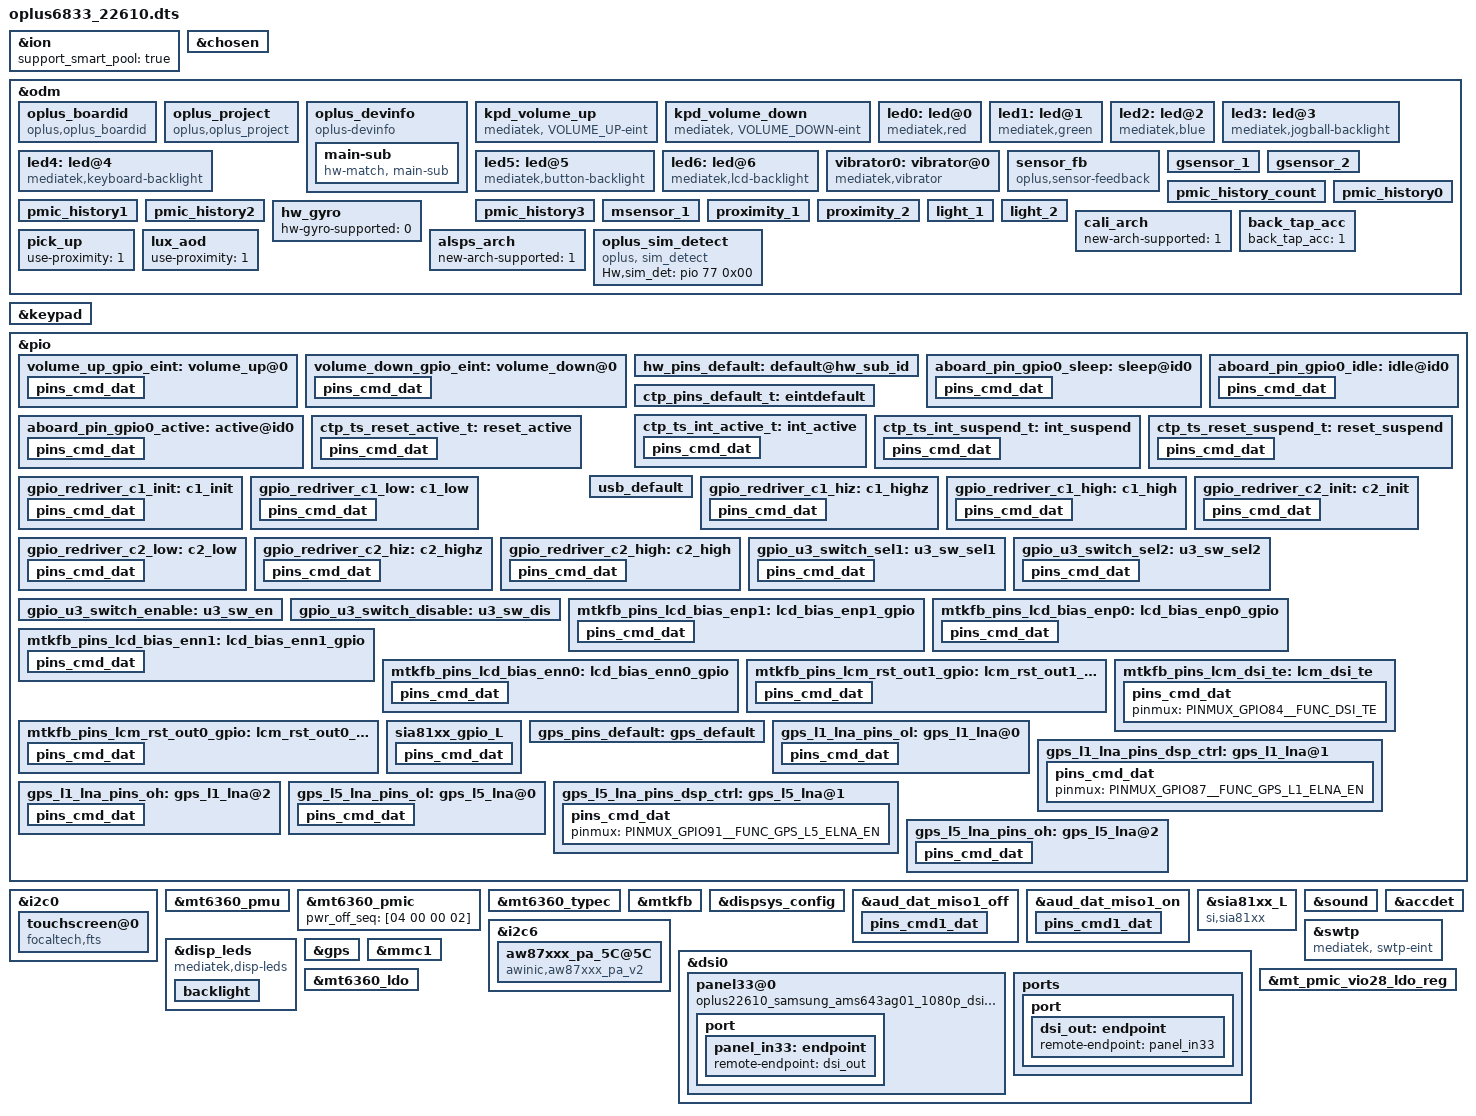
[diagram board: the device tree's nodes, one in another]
// SPDX-License-Identifier: GPL-2.0
/*
 * Copyright (c) 2019 MediaTek Inc.
 *
 */
/dts-v1/;
/plugin/;
#include <dt-bindings/interrupt-controller/irq.h>
#include <dt-bindings/interrupt-controller/arm-gic.h>
#ifndef CONFIG_FPGA_EARLY_PORTING
#include <dt-bindings/pinctrl/mt6833-pinfunc.h>
#endif

/* #ifdef CONFIG_UFF_FINGERPRINT */
#include "mediatek/oplus_uff_22610.dtsi"
/* #endif CONFIG_UFF_FINGERPRINT */

&ion {
	support_smart_pool = "true";
};

/* chosen */
&chosen {
	atag,videolfb-fb_base_l = <0x7e605000>;
	atag,videolfb-fb_base_h = <0x0>;
	atag,videolfb-islcmfound = <1>;
	atag,videolfb-islcm_inited = <0>;
	atag,videolfb-fps= <6000>;
	atag,videolfb-vramSize= <0x1be0000>;
	atag,videolfb-lcmname=
		"nt35595_fhd_dsi_cmd_truly_nt50358_drv";
};

&odm {
	oplus_boardid:oplus_boardid {
		compatible = "oplus,oplus_boardid";
		oplus_boardid,dtsino="22610";//only one u32
		oplus_boardid,pcbmask="0xffff";//all mask 0xffff
	};
	oplus_project:oplus_project {
		compatible = "oplus,oplus_project";
	};

	oplus_devinfo:oplus_devinfo {
		compatible = "oplus-devinfo";
		pinctrl-names = "default", "aboard_gpio0_sleep", "aboard_gpio0_active", "aboard_gpio0_idle";
		pinctrl-0 = <&hw_pins_default>;
		pinctrl-1 = <&aboard_pin_gpio0_sleep>;
		pinctrl-2 = <&aboard_pin_gpio0_active>;
		pinctrl-3 = <&aboard_pin_gpio0_idle>;
		main-sub {
			use_tristate_gpio;
			compatible = "hw-match, main-sub";
			aboard-gpio0 = <&pio 91 0x00>;
			aboard-patterns = <0>;	/*0[high-resistance] 1[pull-down] 2[pull-up]*/
			/*main board*/
			match-projects = <22610>;
		};
	};

	kpd_volume_up:kpd_volume_up {
		compatible = "mediatek, VOLUME_UP-eint";
		interrupt-parent = <&pio>;
		interrupts = <1 IRQ_TYPE_EDGE_FALLING 1 0>;
		debounce = <32000>;
		status = "okay";
	};

	kpd_volume_down:kpd_volume_down {
		compatible = "mediatek, VOLUME_DOWN-eint";
		interrupt-parent = <&pio>;
		interrupts = <80 IRQ_TYPE_EDGE_FALLING 80 0>;
		debounce = <32000>;
		status = "okay";
	};
};
&keypad {
	keypad,volume-up	= <&pio 1 0x00>;
	keypad,volume-down	= <&pio 80 0x00>;
	pinctrl-names = "volume_up_as_int", "volume_down_as_int";
	pinctrl-0 = <&volume_up_gpio_eint>;
	pinctrl-1 = <&volume_down_gpio_eint>;
	status = "okay";
};
&pio {
	volume_up_gpio_eint:volume_up@0{
		pins_cmd_dat {
			pinmux = <PINMUX_GPIO1__FUNC_GPIO1>;
			slew-rate = <0>;  /*direction 0:in, 1:out*/
			input-enable;
		};
	};

	volume_down_gpio_eint:volume_down@0{
		pins_cmd_dat {
			pinmux = <PINMUX_GPIO80__FUNC_GPIO80>;
			slew-rate = <0>;  /*direction 0:in, 1:out*/
			input-enable;
		};
	};

	hw_pins_default:default@hw_sub_id {
	};
	aboard_pin_gpio0_sleep:sleep@id0 {
		pins_cmd_dat {
			pinmux = <PINMUX_GPIO91__FUNC_GPIO91>;
			slew-rate = <0>;
			bias-pull-down;
			input-enable;
		};
	};

	aboard_pin_gpio0_active:active@id0 {
		pins_cmd_dat {
			pinmux = <PINMUX_GPIO91__FUNC_GPIO91>;
			slew-rate = <0>;
			bias-pull-up;
			input-enable;
		};
	};

	aboard_pin_gpio0_idle:idle@id0 {
		pins_cmd_dat {
			pinmux = <PINMUX_GPIO91__FUNC_GPIO91>;
			slew-rate = <0>;
			bias-disable;
			input-enable;
		};
	};
};

/* 2022.12.31,Hawaii add for tp ic 3518 dts bringup */
&i2c0 {
	status = "okay";
	#address-cells = <1>;
	#size-cells = <0>;

	touchscreen@0 {
		compatible = "focaltech,fts";
		reg = <0x38>;
		chip-name = "FT3518";
		status = "okay";

		//spi-max-frequency = <9600000>;	//4800000,9600000,15000000,19200000
		interrupt-parent = <&pio>;
		interrupts = <14 0x2002>;
		irq-gpio = <&pio 14 0x2002>;
		reset-gpio = <&pio 15 0x1>;

		/* Power Config */
		//vdd_2v8-supply  = <&mt_pmic_vtp_ldo_reg>;
		//vdd_2v8_volt = <3000000>;

		/*driver match info*/
		vid_len = <2>;
		tp_type = <8>; /*type:21 txd*/
		platform_support_project = <22610 22705 22706 22740 22741>;
		platform_support_project_dir = <22610 22705 22706 22740 22741>;
		platform_support_project_commandline = "default_commandline", "default_commandline", "default_commandline", "default_commandline", "default_commandline";

		/*panel properities*/
		touchpanel,max-num-support = <10>;
		touchpanel,tx-rx-num = <16 34>;
		touchpanel,panel-coords = <4320 9600>;
		touchpanel,display-coords = <1080 2400>;
		touchpanel,touchmajor-limit = <0 216>;
		touchpanel,report-rate = <120 240>;
		touchpanel,smooth-level = <255 2 15 25 45 60>;
		touchpanel,smooth-level-charging = <255 15 20 25 45 60>;
		touchpanel,sensitive-level = <255 20 16 13 10 5>;
		touchpanel,single-optimized-time = <8>;
		touchpanel,high-frame-rate-time = <20>;

		/*sw-feature*/
		//incell_screen;
		//irq_need_dev_resume_ok;
		fw_edge_limit_support;
		black_gesture_support;
		charger_pump_support;
		headset_pump_support;
		//esd_handle_support;
		//black_gesture_test_support;
		game_switch_support;
		//noflash_support;
		//lcd_trigger_load_tp_fw_support;
		smart_gesture_support;
		pressure_report_support;
		fw_update_app_support;
		health_monitor_v2_support;
		fw_update_in_probe_with_headfile;
		fingerprint_underscreen_support;
		high_resolution_support;
		//disable_suspend_irq_handler_support;
		sportify_aod_gesture_support;
		black_gesture_indep_support;
		exception_upload_support;
		//snr_read_support;

		touchpanel,button-type = <4>;
		touchpanel.button-TRx = <0 0>;
	};

};

&pio {
	ctp_pins_default_t: eintdefault {
	};
	ctp_ts_int_active_t: int_active {
		pins_cmd_dat {
			pinmux = <PINMUX_GPIO14__FUNC_GPIO14>;
			slew-rate = <0>;
			bias-pull-down = <0>;
		};
	};
	ctp_ts_reset_active_t: reset_active {
		pins_cmd_dat {
			pinmux = <PINMUX_GPIO15__FUNC_GPIO15>;
			slew-rate = <1>;
			output-high;
		};
	};
	ctp_ts_int_suspend_t: int_suspend {
		pins_cmd_dat {
			pinmux = <PINMUX_GPIO14__FUNC_GPIO14>;
			slew-rate = <1>;
			output-low;
		};
	};
	ctp_ts_reset_suspend_t: reset_suspend {
		pins_cmd_dat {
			pinmux = <PINMUX_GPIO15__FUNC_GPIO15>;
			slew-rate = <0>;
			output-low;
		};
	};
};
/*TOUCH END*/

/* USB SWITCH GPIO start */
&pio {
	usb_default: usb_default {
	};

	gpio_redriver_c1_init: c1_init {
		pins_cmd_dat {
			pinmux = <PINMUX_GPIO41__FUNC_GPIO41>;
			slew-rate = <1>;
			output-low;
		};
	};

	gpio_redriver_c1_low: c1_low {
		pins_cmd_dat {
			pinmux = <PINMUX_GPIO41__FUNC_GPIO41>;
			slew-rate = <1>;
			output-low;
		};
	};

	gpio_redriver_c1_hiz: c1_highz {
		pins_cmd_dat {
			pinmux = <PINMUX_GPIO41__FUNC_GPIO41>;
			slew-rate= <0>;
			bias-disable;
		};
	};

	gpio_redriver_c1_high: c1_high {
		pins_cmd_dat {
			pinmux = <PINMUX_GPIO41__FUNC_GPIO41>;
			slew-rate = <1>;
			output-high;
		};
	};

	gpio_redriver_c2_init: c2_init {
		pins_cmd_dat {
			pinmux = <PINMUX_GPIO40__FUNC_GPIO40>;
			slew-rate = <1>;
			output-low;
		};
	};

	gpio_redriver_c2_low: c2_low {
		pins_cmd_dat {
			pinmux = <PINMUX_GPIO40__FUNC_GPIO40>;
			slew-rate = <1>;
			output-low;
		};
	};

	gpio_redriver_c2_hiz: c2_highz {
		pins_cmd_dat {
			pinmux = <PINMUX_GPIO40__FUNC_GPIO40>;
			slew-rate= <0>;
			bias-disable;
		};
	};

	gpio_redriver_c2_high: c2_high {
		pins_cmd_dat {
			pinmux = <PINMUX_GPIO40__FUNC_GPIO40>;
			slew-rate = <1>;
			output-high;
		};
	};

	gpio_u3_switch_sel1: u3_sw_sel1 {
		pins_cmd_dat {
			pinmux = <PINMUX_GPIO11__FUNC_GPIO11>;
			slew-rate = <1>;
			output-low;
		};
	};

	gpio_u3_switch_sel2: u3_sw_sel2 {
		pins_cmd_dat {
			pinmux = <PINMUX_GPIO11__FUNC_GPIO11>;
			slew-rate = <1>;
			output-high;
		};
	};

	gpio_u3_switch_enable: u3_sw_en {
	};

	gpio_u3_switch_disable: u3_sw_dis {
	};
};

&mt6360_pmu {
	mt6360,intr_gpio_num = <10>; /* direct defined GPIO num */
	mt6360,intr_gpio = <&pio 10 0x0>;
};

&mt6360_pmic {
	pwr_off_seq = [04 00 00 02];
};

&mt6360_typec {
	mt6360pd,intr_gpio_num = <9>; /* direct defined GPIO num */
	mt6360pd,intr_gpio = <&pio 9 0x0>;
};

#ifndef CONFIG_FPGA_EARLY_PORTING
&pio {
	mtkfb_pins_lcd_bias_enp1: lcd_bias_enp1_gpio {
		pins_cmd_dat {
			pinmux = <PINMUX_GPIO137__FUNC_GPIO137>;
			slew-rate = <1>;
			output-high;
		};
	};

	mtkfb_pins_lcd_bias_enp0: lcd_bias_enp0_gpio {
		pins_cmd_dat {
			pinmux = <PINMUX_GPIO137__FUNC_GPIO137>;
			slew-rate = <1>;
			output-low;
		};
	};

	mtkfb_pins_lcd_bias_enn1: lcd_bias_enn1_gpio {
		pins_cmd_dat {
			pinmux = <PINMUX_GPIO138__FUNC_GPIO138>;
			slew-rate = <1>;
			output-high;
		};
	};

	mtkfb_pins_lcd_bias_enn0: lcd_bias_enn0_gpio {
		pins_cmd_dat {
			pinmux = <PINMUX_GPIO138__FUNC_GPIO138>;
			slew-rate = <1>;
			output-low;
		};
	};

	mtkfb_pins_lcm_rst_out1_gpio: lcm_rst_out1_gpio {
		pins_cmd_dat {
			pinmux = <PINMUX_GPIO86__FUNC_GPIO86>;
			slew-rate = <1>;
			output-high;
		};
	};

	mtkfb_pins_lcm_rst_out0_gpio: lcm_rst_out0_gpio {
		pins_cmd_dat {
			pinmux = <PINMUX_GPIO86__FUNC_GPIO86>;
			slew-rate = <1>;
			output-low;
		};
	};
	mtkfb_pins_lcm_dsi_te: lcm_dsi_te {
		pins_cmd_dat {
			pinmux = <PINMUX_GPIO84__FUNC_DSI_TE>;
		};
	};
};

&mtkfb {
	pinctrl-names = "lcd_bias_enp1_gpio", "lcd_bias_enp0_gpio",
		"lcd_bias_enn1_gpio", "lcd_bias_enn0_gpio",
		"lcm_rst_out1_gpio", "lcm_rst_out0_gpio",
		"mode_te_te";
	pinctrl-0 = <&mtkfb_pins_lcd_bias_enp1>;
	pinctrl-1 = <&mtkfb_pins_lcd_bias_enp0>;
	pinctrl-2 = <&mtkfb_pins_lcd_bias_enn1>;
	pinctrl-3 = <&mtkfb_pins_lcd_bias_enn0>;
	pinctrl-4 = <&mtkfb_pins_lcm_rst_out1_gpio>;
	pinctrl-5 = <&mtkfb_pins_lcm_rst_out0_gpio>;
	pinctrl-6 = <&mtkfb_pins_lcm_dsi_te>;
	status = "okay";
};
&dispsys_config {
	pinctrl-names =
		"lcm_rst_out1_gpio", "lcm_rst_out0_gpio",
		"mode_te_te";
	pinctrl-0 = <&mtkfb_pins_lcm_rst_out1_gpio>;
	pinctrl-1 = <&mtkfb_pins_lcm_rst_out0_gpio>;
	pinctrl-2 = <&mtkfb_pins_lcm_dsi_te>;
	status = "okay";

	helper-value = <0>, /*MTK_DRM_OPT_STAGE*/
		<1>, /*MTK_DRM_OPT_USE_CMDQ*/
		<1>, /*MTK_DRM_OPT_USE_M4U*/
		<0>, /*MTK_DRM_OPT_SODI_SUPPORT*/
		<1>, /*MTK_DRM_OPT_IDLE_MGR*/
		<0>, /*MTK_DRM_OPT_IDLEMGR_SWTCH_DECOUPLE*/
		<0>, /*MTK_DRM_OPT_IDLEMGR_BY_REPAINT*/
		<0>, /*MTK_DRM_OPT_IDLEMGR_ENTER_ULPS*/
		<0>, /*MTK_DRM_OPT_IDLEMGR_KEEP_LP11*/
		<0>, /*MTK_DRM_OPT_DYNAMIC_RDMA_GOLDEN_SETTING*/
		<1>, /*MTK_DRM_OPT_IDLEMGR_DISABLE_ROUTINE_IRQ*/
		<0>, /*MTK_DRM_OPT_MET_LOG*/
		<1>, /*MTK_DRM_OPT_USE_PQ*/
		<1>, /*MTK_DRM_OPT_ESD_CHECK_RECOVERY*/
		<1>, /*MTK_DRM_OPT_ESD_CHECK_SWITCH*/
		<1>, /*MTK_DRM_OPT_PRESENT_FENCE*/
		<0>, /*MTK_DRM_OPT_RDMA_UNDERFLOW_AEE*/
		<1>, /*MTK_DRM_OPT_DSI_UNDERRUN_AEE*/
		<1>, /*MTK_DRM_OPT_HRT*/
		<1>, /*MTK_DRM_OPT_HRT_MODE*/
		<0>, /*MTK_DRM_OPT_DELAYED_TRIGGER*/
		<1>, /*MTK_DRM_OPT_OVL_EXT_LAYER*/
		<0>, /*MTK_DRM_OPT_AOD*/
		<1>, /*MTK_DRM_OPT_RPO*/
		<0>, /*MTK_DRM_OPT_DUAL_PIPE*/
		<0>, /*MTK_DRM_OPT_DC_BY_HRT*/
		<0>, /*MTK_DRM_OPT_OVL_WCG*/
		<0>, /*MTK_DRM_OPT_OVL_SBCH*/
		<1>, /*MTK_DRM_OPT_COMMIT_NO_WAIT_VBLANK*/
		<0>, /*MTK_DRM_OPT_MET*/
		<0>, /*MTK_DRM_OPT_REG_PARSER_RAW_DUMP*/
		<0>, /*MTK_DRM_OPT_VP_PQ*/
		<0>, /*MTK_DRM_OPT_GAME_PQ*/
		<0>, /*MTK_DRM_OPT_MMPATH*/
		<1>, /*MTK_DRM_OPT_HBM*/
		<1>, /*MTK_DRM_OPT_VDS_PATH_SWITCH*/
		<0>, /*MTK_DRM_OPT_LAYER_REC*/
		<1>; /*MTK_DRM_OPT_CLEAR_LAYER*/
};

/* add for dual-mic or singlemic with miso1 */
&aud_dat_miso1_off {
	pins_cmd1_dat {
		pinmux = <PINMUX_GPIO160__FUNC_GPIO160>;
		input-enable;
		bias-pull-down;
	};
};
&aud_dat_miso1_on {
	pins_cmd1_dat {
		pinmux = <PINMUX_GPIO160__FUNC_AUD_DAT_MISO1>;
		input-schmitt-enable;
		bias-disable;
	};
};

&pio {
	sia81xx_gpio_L: sia81xx_gpio_L {
		pins_cmd_dat {
			pinmux = <PINMUX_GPIO94__FUNC_GPIO94>;
			slew-rate = <1>;
			bias-disable;
		};
	};
};

&sia81xx_L {
	compatible = "si,sia81xx";
	si,sia81xx_type = "sia8102";
	si,sia81xx_reset = <&pio 94 0>;
	si,sia81xx_owi = <&pio 94 0>;
	si,sia_boost_vol_support = <1>;
	pinctrl-names = "sia81xx_gpio";
	pinctrl-0 = <&sia81xx_gpio_L>;
	si,sia81xx_disable_pin = <0>;
	/* the same value share a same task
	 * valid value range : 0 ~ 7 */
	timer_task_hdl = <0>;
	channel_num = <0>;
	owi_mode = <1>;
	en_x_filter = <0>;
	en_dynamic_updata_vdd = <1>;
	dynamic_updata_vdd_port = <0x8>;
	algo_is_v2 = <1>;
};

&sound {
	/* this dtsi config for product's special config, AudioHal read ctl 'OPLUS_AUDIO_EXTEN_CONFIG' get the values*
	 * 1st value --> PA type: 0:NXP Pa, 1:Awinic Pa 2:sia81xx Pa*/
	audio_extern_config = <2>;
	si,sia81xx-max-num = <1>;
	si,sia81xx-aux-devs = <&sia81xx_L>;
	si,sia81xx-aux-devs-prefix = "SpkrLeft";
};

&i2c6 {
	aw87xxx_pa_5C@5C {
		compatible = "awinic,aw87xxx_pa_v2";
		reset-gpio = <&pio 94 0>;
		reg = <0x5C>;
		dev_index = < 0 >;
		status = "okay";
	};
};

&dsi0 {
	status = "okay";
	#address-cells = <1>;
	#size-cells = <0>;
	panel33@0 {
		compatible = "oplus22610_samsung_ams643ag01_1080p_dsi_cmd";
		reg = <0>;
		reset-gpios = <&pio 86 0>;
		bias-gpios = <&pio 137 0>, <&pio 138 0>;
		pinctrl-names = "default";
		port {
			panel_in33: endpoint {
				remote-endpoint = <&dsi_out>;
			};
		};
	};
	ports {
		port {
			dsi_out: endpoint {
				remote-endpoint = <&panel_in33>;
			};
		};
	};
};
#endif

/* delete default keys pinctrl
&keypad {
	pinctrl-names = "default";
	pinctrl-0 = <&kpd_pins_default>;
};

&pio {
	kpd_pins_default: kpdgpiodefault {
		pins_cmd_dat {
			pinmux = <PINMUX_GPIO79__FUNC_KPCOL0>;
			bias-pull-up = <MTK_PUPD_SET_R1R0_10>;
			output-low;
			input-schmitt-enable;
		};
	};
};
*/

//#include "mediatek/cust_mt6833_touch_1080x2300.dtsi"
/* accdet start */
&accdet {
	/* accdet micbias voltage: 0x09:2.85v 0x08:2.8v 0x07,
	 * 2.7v;0x05,2.5v;0x02,1.9v
	 */
	accdet-mic-vol = <7>;
	/* accdet pwm_width, pwm_thresh, fall_delay, rise_delay
	 * debounce0, debounce1, debounce3, debounce4
	 * eint pwm_width, eint pwm_thresh
	 * eint deb(debounce0, debounce1, debounce2, debounce3), inv_debounce
	 */

	headset-mode-setting = <0x500 0x500 1 0x1f0
				0x1325 0x800 0x3D4 0x44
				0x0 0x7
				0x5 0x9 0x9 0xd 0xe>;
	/*headset-mode-setting = <0x500 0x500 1 0x1f0
	*                      0x800 0x800 0x20 0x44
	*                      0x4 0x1
	*                      0x5 0x3 0x3 0x5 0xe>;
	*/

	accdet-plugout-debounce = <1>;
	/*1:ACC mode, 2:low cost without in bias, 6:low cost with in bias*/
	accdet-mic-mode = <2>;
	/*0--MD_MAX--UP_MAX--DW_MAX*/
	headset-three-key-threshold = <0 82 170 306>;
	//headset-three-key-threshold = <0 80 220 400>;
	headset-three-key-threshold-CDD = <0 121 192 600>;
	/*0--MD_MAX--VOICE_MAX--UP_MAX--DW_MAX*/
	headset-four-key-threshold = <0 58 121 192 400>;
	/* moisture HW mode config start. Enable moisture detection or not
	 * default use HW mode for moisture detection
	 */
	moisture_detect_enable = <1>;
	/* select VTH to 2v and 500k, use internal resitance */
	eint_use_ext_res = <0>;
	/* enable eint detection mode, if moisture detection enable
	 * eint_detect_mode = moisture_detect_mode;otherwise, select
	 * eint_detect_mode = 4 as DEFAULT
	 */
	eint_detect_mode = <5>;
	/* enable moisture detection mode, if moisture detection enable
	 * eint_detect_mode = moisture_detect_mode
	 */
	moisture_detect_mode = <5>;
	/* select 0: 2.8V; 1: 2.4V; 2: 2V; 3: VTH=MVTH(VTH2) */
	moisture_comp_vth = <2>;
//#ifdef OPLUS_BUG_COMPATIBILITY
	moisture_comp_vref2 = <2>;
//#else
	/* vref2 voltage for different water impedance */
	//moisture_comp_vref2 = <0>;
//#endif
	/* moisture HW mode config end */

	/* moisture SW mode config start, use external resister or not.
	 * DEFAULT NOT NEED
	 */
	moisture_use_ext_res = <0>;
	/* moisture external resister ohm, SW mode by auxadc */
	moisture-external-r = <2000000>;
	/* moisture internal resister ohm, SW mode by auxadc */
	moisture-internal-r = <47000>;
	/* moisture of water resister ohm, SW mode by auxadc*/
	moisture-water-r = <10000>;
	/* moisture SW mode config end */
        //#endif /* VENDOR_EDIT */
	status = "okay";
};
/* accdet end */

//#ifdef OPLUS_FEATURE_SWTP
&swtp {
    compatible = "mediatek, swtp-eint";
};
//#endif  /*OPLUS_FEATURE_SWTP*/

&disp_leds {
	compatible = "mediatek,disp-leds";
	backlight {
		label = "lcd-backlight";
		max-brightness = <22527>;
		led-bits = <14>;
		trans-bits = <14>;
		support_silky_brightness = <1>;
		default-state = "on";
	};
};
&mt_pmic_vio28_ldo_reg {
	regulator-name = "vio28";
	regulator-min-microvolt = <3300000>;
	regulator-max-microvolt = <3300000>;
	regulator-enable-ramp-delay = <1920>;
};

&odm {
	led0:led@0 {
		compatible = "mediatek,red";
		led_mode = <0>;
		data = <1>;
		pwm_config = <0 0 0 0 0>;
	};
	led1:led@1 {
		compatible = "mediatek,green";
		led_mode = <0>;
		data = <1>;
		pwm_config = <0 0 0 0 0>;
	};
	led2:led@2 {
		compatible = "mediatek,blue";
		led_mode = <0>;
		data = <1>;
		pwm_config = <0 0 0 0 0>;
	};
	led3:led@3 {
		compatible = "mediatek,jogball-backlight";
		led_mode = <0>;
		data = <1>;
		pwm_config = <0 0 0 0 0>;
	};
	led4:led@4 {
		compatible = "mediatek,keyboard-backlight";
		led_mode = <0>;
		data = <1>;
		pwm_config = <0 0 0 0 0>;
	};
	led5:led@5 {
		compatible = "mediatek,button-backlight";
		led_mode = <0>;
		data = <1>;
		pwm_config = <0 0 0 0 0>;
	};
	led6:led@6 {
		compatible = "mediatek,lcd-backlight";
		led_mode = <4>;
		data = <1>;
		pwm_config = <0 1 0 0 0>;
	};
	vibrator0:vibrator@0 {
		compatible = "mediatek,vibrator";
	};
	sensor_fb: sensor_fb {
		compatible = "oplus,sensor-feedback";
	};

	/*
	enum {
		LIS3DH,
		LSM6DS3,
		BMI160,
		LIS2HH12,
		LSM6DSM,
		BMI2XY,
		LSM6DSO,
		ICM4X6XX,
		SC7A20,
		BMA4XY,
		BMI3XY,
		ICM4N607,
		BMA2X2,
		MC34X9,
		STK8XXX,
	};
	*/

	gsensor_1: gsensor_1 {
		status = "okay";
		sensor_name = <8>;//SC7A20
		device_name = "sc7a20";
		i2c_num = <2>;
		i2c_addr = <0>;
		direction = <4>;
		eint_num = <3>;
		gyro_cali_version= <2>;
		acc_cali_range= <300 300 300>; //300mg
		device_id = <0>; //0 sc7a20,1 sc7a20e
		filter_param_h  = <8>;
	};
	gsensor_2: gsensor_2 {
		status = "okay";
		sensor_name = <9>;//BMA4XY
		device_name = "bma4xy";
		i2c_num = <2>;
		i2c_addr = <0>;
		direction = <10>;
		eint_num = <3>;
		gyro_cali_version= <2>;
		acc_cali_range= <300 300 300>; //300mg
	};
	/*
	enum {
		AKM09911,
		MMC3530,
		MMC5603,
		MXG4300,
		QMC6308,
	};
	*/

	pmic_history_count:pmic_history_count {
	};
	pmic_history0:pmic_history0 {
	};
	pmic_history1:pmic_history1 {
	};
	pmic_history2:pmic_history2 {
	};
	pmic_history3:pmic_history3 {
	};

	msensor_1: msensor_1 {
		status = "okay";
		sensor_name = <2>;//MMC5603
		i2c_num = <0>;
		i2c_addr = <48>;
		direction = <1>;
		eint_num = <0>;
		soft-mag-parameter = <9990 0 115 1 352 0 65 0 9840 0 70 0 80 0 407 1 10204 0>;
	};

	/*
	enum {
		TMD2725,
		APSD9922,
		STK3335,
		STK3331,
		STK2232,
		TCS3701,
		STK32600,
		STK33502,
		MN78911,
		TMD2755x12,
	};
	*/
	proximity_1: proximity_1 {
		status = "okay";
		sensor_name = <6>;//STK32600
		i2c_num = <0>;
		i2c_addr = <0x48>;
		direction = <4>;
		eint_num = <2>;
		low_step = <300>;
		high_step = <400>;
		low_limit = <650>;
		high_limit = <1050>;
		dirty_low_step = <300>;
		dirty_high_step = <400>;
		ps_dirty_limit = <1800>;
		ps_ir_limit = <2000>;
		ps_adjust_min = <0>;
		ps_adjust_max = <1850>;
		sampling_count = <5>;
		step_max = <400>;
		step_min = <100>;
		step_div = <2000>;
		anti_shake_delta = <70>;
		dynamic_cali_max = <2000>;
		raw2offset_radio = <1000>;
		offset_max = <60000>;
		offset_range_min = <0>;
		offset_range_max = <65534>;
		force_cali_limit = <2000>;
		cali_jitter_limit = <30>;
		cal_offset_margin = <3000>;
		is_use_force_cali = <1>;
	};
	proximity_2: proximity_2 {
		status = "okay";
		sensor_name = <5>;//TCS3701
		i2c_num = <0>;
		i2c_addr = <57>;
		direction = <4>;
		eint_num = <12>;
		low_step = <300>;
		high_step = <400>;
		low_limit = <400>;
		high_limit = <600>;
		dirty_low_step = <180>;
		dirty_high_step = <250>;
		ps_dirty_limit = <1023>;
		ps_ir_limit = <500>;
		ps_adjust_min = <0>;
		ps_adjust_max = <600>;
		sampling_count = <5>;
		step_max = <400>;
		step_min = <110>;
		step_div = <1500>;
		anti_shake_delta = <80>;
		dynamic_cali_max = <1024>;
		raw2offset_radio = <20800>;
		offset_max = <250>;
		offset_range_min = <255>;
		offset_range_max = <255>;
		force_cali_limit = <2000>;
		cali_jitter_limit = <30>;
		cal_offset_margin = <120>;
	};
	light_1: light_1 {
		status = "okay";
		sensor_name = <6>;//STK32600
		i2c_num = <0>;
		i2c_addr = <0x48>;
		direction = <4>;
		eint_num = <2>;
		als_buffer_length =<8>;
		als_ratio = <110>;
		als_type = <2>;//1:normal;2:under screen
		device_name = "stk32600";
		use_als_c2 = <1>;
	};
	light_2: light_2 {
		status = "okay";
		sensor_name = <5>;//TCS3701
		i2c_num = <0>;
		i2c_addr = <57>;
		direction = <4>;
		eint_num = <12>;
		als_buffer_length = <10>;
		als_ratio = <110>;
		als_type = <2>;//1:normal;2:under screen
		device_name = "tcs3701";
	};
	hw_gyro: hw_gyro {
		status = "okay";
		hw-gyro-supported = <0>;
	};
	cali_arch: cali_arch {
		status = "okay";
		new-arch-supported = <1>;
	};
	back_tap_acc: back_tap_acc {
		status = "okay";
		back_tap_acc = <1>;
	};
	pick_up: pick_up {
		status = "okay";
		use-proximity = <1>;
	};
	lux_aod: lux_aod {
		status = "okay";
		use-proximity = <1>;
	};
	alsps_arch: alsps_arch {
		status = "okay";
		new-arch-supported = <1>;
	};
    oplus_sim_detect {
        compatible = "oplus, sim_detect";
        Hw,sim_det = <&pio 77 0x00>;
    };
};

/* GPS GPIO standardization start */
&pio {
	gps_pins_default: gps_default {
	};

	gps_l1_lna_pins_ol: gps_l1_lna@0 {
		pins_cmd_dat {
			pinmux = <PINMUX_GPIO87__FUNC_GPIO87>;
			output-low;
		};
	};
	gps_l1_lna_pins_dsp_ctrl: gps_l1_lna@1 {
		pins_cmd_dat {
			pinmux = <PINMUX_GPIO87__FUNC_GPS_L1_ELNA_EN>;
		};
	};
	gps_l1_lna_pins_oh: gps_l1_lna@2 {
		pins_cmd_dat {
			pinmux = <PINMUX_GPIO87__FUNC_GPIO87>;
			output-high;
		};
	};

	gps_l5_lna_pins_ol: gps_l5_lna@0 {
		pins_cmd_dat {
			pinmux = <PINMUX_GPIO91__FUNC_GPIO91>;
			output-low;
		};
	};
	gps_l5_lna_pins_dsp_ctrl: gps_l5_lna@1 {
		pins_cmd_dat {
			pinmux = <PINMUX_GPIO91__FUNC_GPS_L5_ELNA_EN>;
		};
	};
	gps_l5_lna_pins_oh: gps_l5_lna@2 {
		pins_cmd_dat {
			pinmux = <PINMUX_GPIO91__FUNC_GPIO91>;
			output-high;
		};
	};
};

&gps {
	pinctrl-names = "default",
		"gps_l1_lna_disable",
		"gps_l1_lna_dsp_ctrl",
		"gps_l1_lna_enable",
		"gps_l5_lna_disable",
		"gps_l5_lna_dsp_ctrl",
		"gps_l5_lna_enable";
	pinctrl-0 = <&gps_pins_default>;
	pinctrl-1 = <&gps_l1_lna_pins_ol>;
	pinctrl-2 = <&gps_l1_lna_pins_dsp_ctrl>;
	pinctrl-3 = <&gps_l1_lna_pins_oh>;
	pinctrl-4 = <&gps_l5_lna_pins_ol>;
	pinctrl-5 = <&gps_l5_lna_pins_dsp_ctrl>;
	pinctrl-6 = <&gps_l5_lna_pins_oh>;
	status = "okay";
};

/* GPS GPIO standardization end */
#include "mediatek/cust_mt6833_camera_22610.dtsi"
#include <oplus6833_22610/cust.dtsi>

//#ifdef OPLUS_FEATURE_CHG_BASIC
#include "mediatek/oplus_charge_mt6833_22610.dtsi"
//#endif
&mmc1 {
    cd-gpios = <&pio 4 0>;
    status = "okay";
    vmmc-supply = <&mt_pmic_vmch_ldo_reg>;
};
&mt6360_ldo {
	sdcard_det_en = <1>;
	sdcard_hlact = <0>;
};
/*End of this file, DO NOT ADD ANYTHING HERE*/
